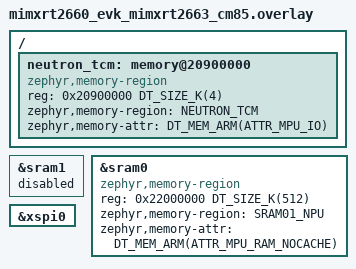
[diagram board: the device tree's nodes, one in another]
/*
 * Copyright 2026 NXP
 * SPDX-License-Identifier: Apache-2.0
 */

#include <zephyr/dt-bindings/memory-attr/memory-attr-arm.h>

/* Combine SRAM0 and SRAM1 into a non-cacheable NPU memory region. */
&sram1 {
	status = "disabled";
};

&sram0 {
	compatible = "zephyr,memory-region", "mmio-sram";
	reg = <0x22000000 DT_SIZE_K(512)>;
	zephyr,memory-region = "SRAM01_NPU";
	zephyr,memory-attr = <DT_MEM_ARM(ATTR_MPU_RAM_NOCACHE)>;
};

/*
 * NPU window the Neutron driver accesses. Declared with ATTR_MPU_IO so
 * the MPU code maps it Device-nGnRE from devicetree, instead of
 * soc_neutron_init() hardcoding an ARM_MPU_SetRegion() call with a fixed
 * region index.
 */
/ {
	neutron_tcm: memory@20900000 {
		compatible = "zephyr,memory-region", "mmio-sram";
		reg = <0x20900000 DT_SIZE_K(4)>;
		zephyr,memory-region = "NEUTRON_TCM";
		zephyr,memory-attr = <DT_MEM_ARM(ATTR_MPU_IO)>;
	};
};

/* Keep XSPI boot-header offsets enabled for the XIP image. */
&xspi0 {
	status = "okay";
};
